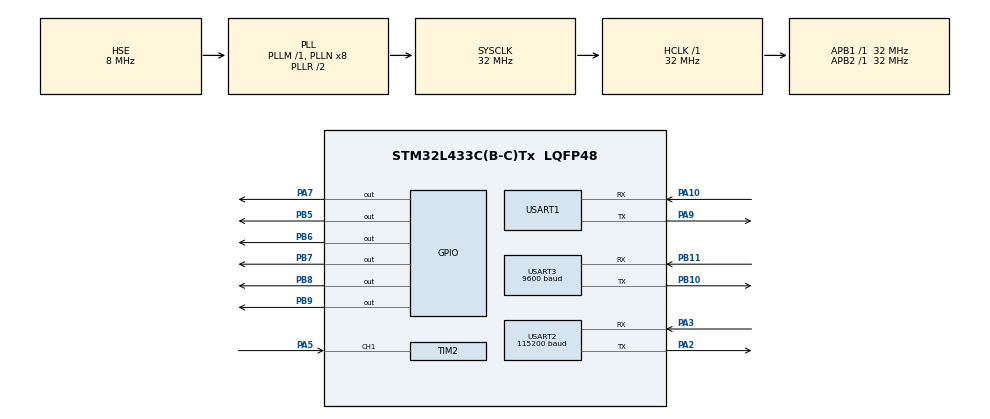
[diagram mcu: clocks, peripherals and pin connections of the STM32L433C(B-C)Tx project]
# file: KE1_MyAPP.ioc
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Mcu.Family=STM32L4
NVIC.USART3_IRQn=true\:1\:0\:true\:false\:true\:true\:true
RCC.MSI_VALUE=4000000
RCC.PLLSourceVirtual=RCC_PLLSOURCE_HSE
SH.S_TIM2_CH1.0=TIM2_CH1,Input_Capture1_from_TI1
RCC.CortexFreq_Value=32000000
TIM2.Channel-Input_Capture1_from_TI1=TIM_CHANNEL_1
PA10.Mode=Asynchronous
PB10.Mode=Asynchronous
PH0-OSC_IN\ (PH0).Signal=RCC_OSC_IN
PC15-OSC32_OUT\ (PC15).Signal=RCC_OSC32_OUT
PC15-OSC32_OUT\ (PC15).Mode=LSE-External-Oscillator
PB11.Signal=USART3_RX
NVIC.USART2_IRQn=true\:3\:0\:true\:false\:true\:true\:true
USART2.BaudRate=115200
PH1-OSC_OUT\ (PH1).Signal=RCC_OSC_OUT
RCC.SYSCLKSource=RCC_SYSCLKSOURCE_PLLCLK
ProjectManager.StackSize=0x400
PC14-OSC32_IN\ (PC14).Mode=LSE-External-Oscillator
USART3.VirtualMode-Asynchronous=VM_ASYNC
USART1.VirtualMode-Asynchronous=VM_ASYNC
PA3.Mode=Asynchronous
PA9.Mode=Asynchronous
USART3.BaudRate=9600
PB11.Mode=Asynchronous
ProjectManager.TargetToolchain=STM32CubeIDE
RCC.HCLKFreq_Value=32000000
RCC.APB2TimFreq_Value=32000000
PA9.Signal=USART1_TX
PB6.Signal=GPIO_Output
PB5.PinState=GPIO_PIN_SET
RCC.USBFreq_Value=32000000
RCC.AHBFreq_Value=32000000
PB10.Signal=USART3_TX
PA5.Signal=S_TIM2_CH1
PH1-OSC_OUT\ (PH1).Mode=HSE-External-Oscillator
RCC.HSE_VALUE=8000000
board=custom
USART2.VirtualMode-Asynchronous=VM_ASYNC
RCC.VCOOutputFreq_Value=64000000
RCC.APB2Freq_Value=32000000
VP_TIM2_VS_ClockSourceINT.Mode=Internal
NVIC.TIM2_IRQn=true\:0\:0\:false\:false\:true\:true\:true
RCC.ADCFreq_Value=32000000
PB7.Signal=GPIO_Output
TIM2.Period=0xFFFF
Mcu.Name=STM32L433C(B-C)Tx
PA2.Signal=USART2_TX
PB7.PinState=GPIO_PIN_SET
RCC.SYSCLKFreq_VALUE=32000000
Mcu.Package=LQFP48
PB5.Signal=GPIO_Output
PB9.Signal=GPIO_Output
TIM2.Prescaler=32-1
PC14-OSC32_IN\ (PC14).Signal=RCC_OSC32_IN
PB6.PinState=GPIO_PIN_SET
PA10.Signal=USART1_RX
ProjectManager.HeapSize=0x200
RCC.HSI_VALUE=16000000
NVIC.PriorityGroup=NVIC_PRIORITYGROUP_4
RCC.APB1TimFreq_Value=32000000
PA2.Mode=Asynchronous
PB8.Signal=GPIO_Output
RCC.APB1Freq_Value=32000000
PH0-OSC_IN\ (PH0).Mode=HSE-External-Oscillator
RCC.HSI48_VALUE=48000000
PA3.Signal=USART2_RX
PA7.Signal=GPIO_Output

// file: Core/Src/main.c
/* USER CODE BEGIN Header */
/**
  ******************************************************************************
  * @file           : main.c
  * @brief          : Main program body
  ******************************************************************************
  * @attention
  *
  * <h2><center>&copy; Copyright (c) 2021 STMicroelectronics.
  * All rights reserved.</center></h2>
  *
  * This software component is licensed by ST under BSD 3-Clause license,
  * the "License"; You may not use this file except in compliance with the
  * License. You may obtain a copy of the License at:
  *                        opensource.org/licenses/BSD-3-Clause
  *
  ******************************************************************************
  */
/* USER CODE END Header */
#include "main.h"
#include "tim.h"
#include "usart.h"
#include "gpio.h"

/* USER CODE BEGIN Includes */
#include <stdio.h>
#include <string.h>

#include "oled.h"
/* USER CODE END Includes */

void SystemClock_Config(void);

int main(void)
{
  /* USER CODE BEGIN 1 */
//  uint8_t aucData[128] = {0};
//  uint16_t usReadLen = 0, usReadTimeout = 1000;
  /* USER CODE END 1 */

  /* MCU Configuration--------------------------------------------------------*/

  /* Reset of all peripherals, Initializes the Flash interface and the Systick. */
  HAL_Init();

  /* Configure the system clock */
  SystemClock_Config();

  /* Initialize all configured peripherals */
  MX_GPIO_Init();
  MX_USART1_UART_Init();
  MX_USART2_UART_Init();
  MX_USART3_UART_Init();
  MX_TIM2_Init();
  /* USER CODE BEGIN 2 */
  UART_Enable_Receive_IT();
  HAL_TIM_IC_Start_IT(&htim2,TIM_CHANNEL_1);
  /* USER CODE END 2 */

  /* Infinite loop */
  /* USER CODE BEGIN WHILE */
  printf("Hello my APP v0.0.2\r\n");

  OLED_Init();
  OLED_DrawLogo();

  HAL_Delay(1000);
  OLED_Clear();
  OLED_Show_MyBilibili();
  HAL_Delay(1000);
  while (1)
  {
    /* USER CODE END WHILE */

    /* USER CODE BEGIN 3 */

	  Ultrasonic_Trig_Start();
	  HAL_Delay(1000);

  }
  /* USER CODE END 3 */
}

void SystemClock_Config(void)
{
  RCC_OscInitTypeDef RCC_OscInitStruct = {0};
  RCC_ClkInitTypeDef RCC_ClkInitStruct = {0};
  RCC_PeriphCLKInitTypeDef PeriphClkInit = {0};

  /** Initializes the RCC Oscillators according to the specified parameters
  * in the RCC_OscInitTypeDef structure.
  */
  RCC_OscInitStruct.OscillatorType = RCC_OSCILLATORTYPE_HSE;
  RCC_OscInitStruct.HSEState = RCC_HSE_ON;
  RCC_OscInitStruct.PLL.PLLState = RCC_PLL_ON;
  RCC_OscInitStruct.PLL.PLLSource = RCC_PLLSOURCE_HSE;
  RCC_OscInitStruct.PLL.PLLM = 1;
  RCC_OscInitStruct.PLL.PLLN = 8;
  RCC_OscInitStruct.PLL.PLLP = RCC_PLLP_DIV7;
  RCC_OscInitStruct.PLL.PLLQ = RCC_PLLQ_DIV2;
  RCC_OscInitStruct.PLL.PLLR = RCC_PLLR_DIV2;
  if (HAL_RCC_OscConfig(&RCC_OscInitStruct) != HAL_OK)
  {
    Error_Handler();
  }
  /** Initializes the CPU, AHB and APB buses clocks
  */
  RCC_ClkInitStruct.ClockType = RCC_CLOCKTYPE_HCLK|RCC_CLOCKTYPE_SYSCLK
                              |RCC_CLOCKTYPE_PCLK1|RCC_CLOCKTYPE_PCLK2;
  RCC_ClkInitStruct.SYSCLKSource = RCC_SYSCLKSOURCE_PLLCLK;
  RCC_ClkInitStruct.AHBCLKDivider = RCC_SYSCLK_DIV1;
  RCC_ClkInitStruct.APB1CLKDivider = RCC_HCLK_DIV1;
  RCC_ClkInitStruct.APB2CLKDivider = RCC_HCLK_DIV1;

  if (HAL_RCC_ClockConfig(&RCC_ClkInitStruct, FLASH_LATENCY_1) != HAL_OK)
  {
    Error_Handler();
  }
  PeriphClkInit.PeriphClockSelection = RCC_PERIPHCLK_USART1|RCC_PERIPHCLK_USART2
                              |RCC_PERIPHCLK_USART3;
  PeriphClkInit.Usart1ClockSelection = RCC_USART1CLKSOURCE_PCLK2;
  PeriphClkInit.Usart2ClockSelection = RCC_USART2CLKSOURCE_PCLK1;
  PeriphClkInit.Usart3ClockSelection = RCC_USART3CLKSOURCE_PCLK1;
  if (HAL_RCCEx_PeriphCLKConfig(&PeriphClkInit) != HAL_OK)
  {
    Error_Handler();
  }
  /** Configure the main internal regulator output voltage
  */
  if (HAL_PWREx_ControlVoltageScaling(PWR_REGULATOR_VOLTAGE_SCALE1) != HAL_OK)
  {
    Error_Handler();
  }
}

void Error_Handler(void)
{
  __disable_irq();
  while (1)
  {
  }
}

/************************ (C) COPYRIGHT STMicroelectronics *****END OF FILE****/
